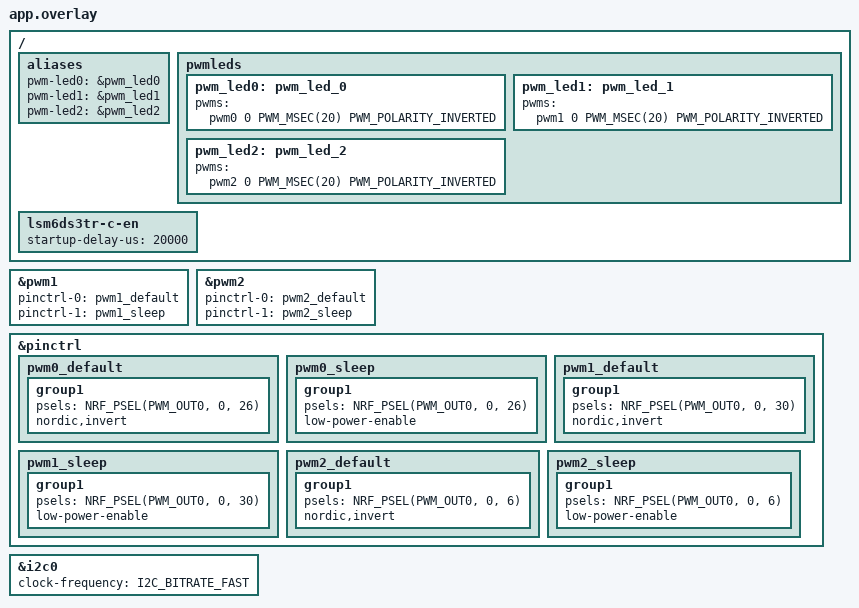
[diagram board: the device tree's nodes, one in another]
/ {
	aliases {
		pwm-led0 = &pwm_led0;
		pwm-led1 = &pwm_led1;
		pwm-led2 = &pwm_led2;
	};

	pwmleds {
		pwm_led0: pwm_led_0 {
			status = "okay";
			pwms = <&pwm0 0 PWM_MSEC(20) PWM_POLARITY_INVERTED>;
		};

		pwm_led1: pwm_led_1 {
			status = "okay";
			pwms = <&pwm1 0 PWM_MSEC(20) PWM_POLARITY_INVERTED>;
		};

		pwm_led2: pwm_led_2 {
			status = "okay";
			pwms = <&pwm2 0 PWM_MSEC(20) PWM_POLARITY_INVERTED>;
		};
	};

	lsm6ds3tr-c-en {
		startup-delay-us = <20000>;
	};

};

&pwm1 {
	status = "okay";
	pinctrl-0 = <&pwm1_default>;
	pinctrl-1 = <&pwm1_sleep>;
	pinctrl-names = "default", "sleep";
};

&pwm2 {
	status = "okay";
	pinctrl-0 = <&pwm2_default>;
	pinctrl-1 = <&pwm2_sleep>;
	pinctrl-names = "default", "sleep";
};

&pinctrl {
	pwm0_default: pwm0_default {
		group1 {
			psels = <NRF_PSEL(PWM_OUT0, 0, 26)>;
			nordic,invert;
		};
	};

	pwm0_sleep: pwm0_sleep {
		group1 {
			psels = <NRF_PSEL(PWM_OUT0, 0, 26)>;
			low-power-enable;
		};
	};

	pwm1_default: pwm1_default {
		group1 {
			psels = <NRF_PSEL(PWM_OUT0, 0, 30)>;
			nordic,invert;
		};
	};
	pwm1_sleep: pwm1_sleep {
		group1 {
			psels = <NRF_PSEL(PWM_OUT0, 0, 30)>;
			low-power-enable;
		};
	};

	pwm2_default: pwm2_default {
		group1 {
			psels = <NRF_PSEL(PWM_OUT0, 0, 6)>;
			nordic,invert;
		};
	};
	pwm2_sleep: pwm2_sleep {
		group1 {
			psels = <NRF_PSEL(PWM_OUT0, 0, 6)>;
			low-power-enable;
		};
	};

};

&i2c0 {
	clock-frequency = <I2C_BITRATE_FAST>;
};
